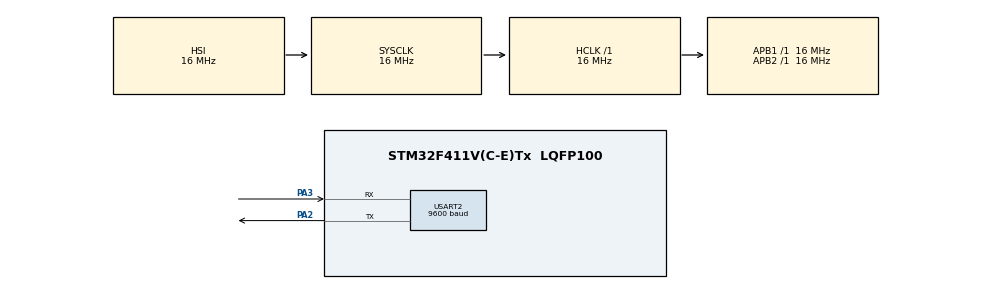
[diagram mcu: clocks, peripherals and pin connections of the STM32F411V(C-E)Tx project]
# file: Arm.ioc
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Mcu.Family=STM32F4
Mcu.Name=STM32F411V(C-E)Tx
Mcu.Package=LQFP100
NVIC.PriorityGroup=NVIC_PRIORITYGROUP_4
PA2.Mode=Asynchronous
PA2.Signal=USART2_TX
PA3.Mode=Asynchronous
PA3.Signal=USART2_RX
ProjectManager.HeapSize=0x200
ProjectManager.StackSize=0x400
ProjectManager.TargetToolchain=STM32CubeIDE
RCC.AHBFreq_Value=16000000
RCC.APB1Freq_Value=16000000
RCC.APB2Freq_Value=16000000
RCC.CortexFreq_Value=16000000
RCC.HSE_VALUE=25000000
RCC.HSI_VALUE=16000000
RCC.LSE_VALUE=32768
RCC.SYSCLKFreq_VALUE=16000000
RCC.VCOOutputFreq_Value=192000000
USART2.BaudRate=9600
USART2.VirtualMode=VM_ASYNC
board=custom

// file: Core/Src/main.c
/* USER CODE BEGIN Header */
/**
  ******************************************************************************
  * @file           : main.c
  * @brief          : Main program body
  ******************************************************************************
  * @attention
  *
  * <h2><center>&copy; Copyright (c) 2021 STMicroelectronics.
  * All rights reserved.</center></h2>
  *
  * This software component is licensed by ST under BSD 3-Clause license,
  * the "License"; You may not use this file except in compliance with the
  * License. You may obtain a copy of the License at:
  *                        opensource.org/licenses/BSD-3-Clause
  *
  ******************************************************************************
  */
/* USER CODE END Header */
#include "main.h"

/* USER CODE BEGIN PD */
#define GET_LOW_BYTE(A) (uint8_t)((A))

#define GET_HIGH_BYTE(A) (uint8_t)((A) >> 8)
/* USER CODE END PD */

UART_HandleTypeDef huart2;

void SystemClock_Config(void);
static void MX_GPIO_Init(void);
static void MX_USART2_UART_Init(void);
/* USER CODE BEGIN PFP */
void moveServos(uint8_t* servoNum, uint32_t* angles, uint8_t length);
void resetServos();
/* USER CODE END PFP */

/* USER CODE BEGIN 0 */

/* A function that moves the servos defined in servoNum to their corresponding index in angles.
 * The parameters of values to send out are based on:
 * 	https://www.dropbox.com/sh/ykbn480cpidmmej/AACul8lJTQXZdX2APnYCorRca?dl=0&preview=LSC+Series+Servo+Controller+Communication+Protocol+V1.2.pdf
 *
 * servoNum: Array of servo ID values. This doesn't need to be 6 long, just put the values you want to move
 * 		- Servo 1 doesn't work
 * 		- Servo 2 is the claw rotation
 * 		- Servo 3 is the fine vertical pivot
 * 		- Servo 4 is the medium vertical pivot
 * 		- Servo 5 is the large vertical pivot
 * 		- Servo 6 controls the claw's pinching
 *
 * 	angles: Array of angles for each corresponding servo in servoNum
 * 		- 1000 = bottom of range
 * 		- 2000 = top of range
 *
 * 	length: length of both servoNum array and angles array
 */
void moveServos(uint8_t* servos, uint32_t* angles, uint8_t length)
{
	uint16_t time = 1000; //default time because why not

	uint8_t data[7 + (length * 3)];
	data[0] = 0x55; //header 1
	data[1] = 0x55; //header 2
	data[2] = 0x05 + (length * 3); //length
	data[3] = 0x03; //cmd
	data[4] = length; //# servos
	data[5] = GET_LOW_BYTE(time); //lower 8 time
	data[6] = GET_HIGH_BYTE(time); //upper 8 time
	for (int i = 0; i < length; i++)
	{
		data[7 + (i * 3)] = servos[i];
		data[8 + (i * 3)] = GET_LOW_BYTE(angles[i]);
		data[9 + (i * 3)] = GET_HIGH_BYTE(angles[i]);
	}
	HAL_UART_Transmit(&huart2, data, 7 + (length * 3), time + 250);
	HAL_Delay(3000);
}

void resetServos()
{
	uint8_t length = 5;
	uint8_t servos[length];
	uint32_t angles[length];
	for(int i = 0; i < length; i++)
	{
		servos[i] = i + 2;
		angles[i] = 1500;
	}
//	angles[1] = 600;
	angles[4] = 2000;
	moveServos(servos, angles, length);
}
/* USER CODE END 0 */

int main(void)
{

  /* MCU Configuration--------------------------------------------------------*/

  /* Reset of all peripherals, Initializes the Flash interface and the Systick. */
  HAL_Init();

  /* Configure the system clock */
  SystemClock_Config();

  /* Initialize all configured peripherals */
  MX_GPIO_Init();
  MX_USART2_UART_Init();
  /* USER CODE BEGIN 2 */

  uint8_t length = 5;
  uint8_t servos[length];
  uint32_t angles[length];
  for (int i = 0; i < length; i++)
  {
	  servos[i] = i + 2;
	  angles[i] = 1500;
  }

  moveServos(servos, angles, length);
  // Claw pivot servo - doesn't ever need to change
  angles[0] = 1500;

  //Top arm servo -
  angles[1] = 1000;
  //600 down straight
  //1500 right angle

  // Mid-arm servo
  angles[2] = 400;
  // 400 forwards down

  // Base servo
  angles[3] = 2200;
  //2200 forwards down - BE CAREFUL THIS PUTS IT REALLY LOW
  //800 backwards down

  // Claw
  // 1500 open completely
  // 2500 closed with contact
  angles[4] = 1500;
  /* USER CODE END 2 */

  /* Infinite loop */
  /* USER CODE BEGIN WHILE */
  moveServos(servos, angles, length);

  //Grab the object
  angles[4] = 2000;
  moveServos(servos, angles, length);

  //Move the arm backwards
  angles[3] = 1500;
  moveServos(servos, angles, length);
  angles[1] = 1500;
  angles[2] = 1500;
  angles[3] = 1500;
  angles[4] = 2000;
  moveServos(servos, angles, length);

  //Drop the item
  angles[4] = 1500;
  moveServos(servos, angles, length);

  while (1)
  {
    /* USER CODE END WHILE */

    /* USER CODE BEGIN 3 */

//	  moveServos(servos, angles, length);
//	  HAL_Delay(3000);
//	  angles[4] = angles[4] == 1500 ? 1500 : 2000;
//	  moveServos(servos, angles, length);
//	  HAL_Delay(3000);
  }
  /* USER CODE END 3 */
}

void SystemClock_Config(void)
{
  RCC_OscInitTypeDef RCC_OscInitStruct = {0};
  RCC_ClkInitTypeDef RCC_ClkInitStruct = {0};

  /** Configure the main internal regulator output voltage
  */
  __HAL_RCC_PWR_CLK_ENABLE();
  __HAL_PWR_VOLTAGESCALING_CONFIG(PWR_REGULATOR_VOLTAGE_SCALE1);
  /** Initializes the RCC Oscillators according to the specified parameters
  * in the RCC_OscInitTypeDef structure.
  */
  RCC_OscInitStruct.OscillatorType = RCC_OSCILLATORTYPE_HSI;
  RCC_OscInitStruct.HSIState = RCC_HSI_ON;
  RCC_OscInitStruct.HSICalibrationValue = RCC_HSICALIBRATION_DEFAULT;
  RCC_OscInitStruct.PLL.PLLState = RCC_PLL_NONE;
  if (HAL_RCC_OscConfig(&RCC_OscInitStruct) != HAL_OK)
  {
    Error_Handler();
  }
  /** Initializes the CPU, AHB and APB buses clocks
  */
  RCC_ClkInitStruct.ClockType = RCC_CLOCKTYPE_HCLK|RCC_CLOCKTYPE_SYSCLK
                              |RCC_CLOCKTYPE_PCLK1|RCC_CLOCKTYPE_PCLK2;
  RCC_ClkInitStruct.SYSCLKSource = RCC_SYSCLKSOURCE_HSI;
  RCC_ClkInitStruct.AHBCLKDivider = RCC_SYSCLK_DIV1;
  RCC_ClkInitStruct.APB1CLKDivider = RCC_HCLK_DIV1;
  RCC_ClkInitStruct.APB2CLKDivider = RCC_HCLK_DIV1;

  if (HAL_RCC_ClockConfig(&RCC_ClkInitStruct, FLASH_LATENCY_0) != HAL_OK)
  {
    Error_Handler();
  }
}

static void MX_USART2_UART_Init(void)
{

  huart2.Instance = USART2;
  huart2.Init.BaudRate = 9600;
  huart2.Init.WordLength = UART_WORDLENGTH_8B;
  huart2.Init.StopBits = UART_STOPBITS_1;
  huart2.Init.Parity = UART_PARITY_NONE;
  huart2.Init.Mode = UART_MODE_TX_RX;
  huart2.Init.HwFlowCtl = UART_HWCONTROL_NONE;
  huart2.Init.OverSampling = UART_OVERSAMPLING_16;
  if (HAL_UART_Init(&huart2) != HAL_OK)
  {
    Error_Handler();
  }

}

static void MX_GPIO_Init(void)
{

  /* GPIO Ports Clock Enable */
  __HAL_RCC_GPIOA_CLK_ENABLE();

}

void Error_Handler(void)
{
}

/************************ (C) COPYRIGHT STMicroelectronics *****END OF FILE****/
